AUTOSAR XML (schema 00050)
package /ComponentTypes
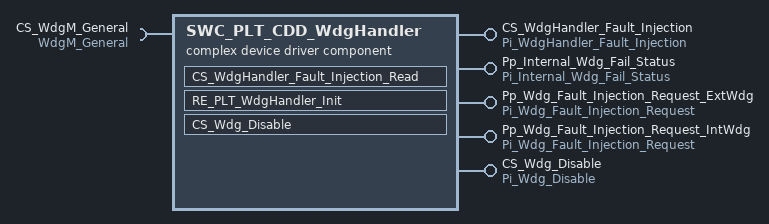
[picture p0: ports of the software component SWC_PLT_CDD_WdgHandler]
  complex device driver sw component type SWC_PLT_CDD_WdgHandler
    5 x provide port:
      CS_WdgHandler_Fault_Injection: server-com-spec{operation=Read, queue-length=1}, provided-interface=Pi_WdgHandler_Fault_Injection
      Pp_Internal_Wdg_Fail_Status: nonqueued-sender-com-spec{data-element=Internal_Wdg_Fail_Status, init-value=0}, provided-interface=Pi_Internal_Wdg_Fail_Status
      Pp_Wdg_Fault_Injection_Request_ExtWdg: nonqueued-sender-com-spec=De_Wdg_Fault_Injection_Request, provided-interface=Pi_Wdg_Fault_Injection_Request
      Pp_Wdg_Fault_Injection_Request_IntWdg: nonqueued-sender-com-spec{data-element=De_Wdg_Fault_Injection_Request, init-value=0}, provided-interface=Pi_Wdg_Fault_Injection_Request
      CS_Wdg_Disable: server-com-spec{operation=Read, queue-length=1}, provided-interface=Pi_Wdg_Disable
    require port CS_WdgM_General: required-interface=WdgM_General
      required-com-specs:
        DeactivateSupervisionEntity
        ActivateSupervisionEntity
        GetFirstExpiredSEID
        SetMode
        PerformReset
        GetLocalStatus
        GetGlobalStatus
        GetMode
    behavior SWC_PLT_CDD_WdgHandler_InternalBehavior: handle-termination-and-restart=NO-SUPPORT
      operation invoked event OIT_CS_WdgHandler_Fault_Injection_Read_CS_WdgHandler_Fault_Injection_Read: start-on-event=CS_WdgHandler_Fault_Injection_Read, operation=CS_WdgHandler_Fault_Injection.Read
      init event SWC_PLT_CDD_WdgHandler_InitEvent: start-on-event=RE_PLT_WdgHandler_Init
      operation invoked event OIT_CS_Wdg_Disable_Read_CS_Wdg_Disable_Read: start-on-event=CS_Wdg_Disable, operation=CS_Wdg_Disable.Read
      runnable CS_WdgHandler_Fault_Injection_Read
      runnable RE_PLT_WdgHandler_Init
        data-send-points:
          access SEND_Pp_Internal_Wdg_Fail_Status_Internal_Wdg_Fail_Status: accessed-variable=Pp_Internal_Wdg_Fail_Status.Internal_Wdg_Fail_Status
          access SEND_Pp_Wdg_Fault_Injection_Request_ExtWdg_De_Wdg_Fault_Injection_Request: accessed-variable=Pp_Wdg_Fault_Injection_Request_ExtWdg.De_Wdg_Fault_Injection_Request
          access SEND_Pp_Wdg_Fault_Injection_Request_IntWdg_De_Wdg_Fault_Injection_Request: accessed-variable=Pp_Wdg_Fault_Injection_Request_IntWdg.De_Wdg_Fault_Injection_Request
      runnable CS_Wdg_Disable: can-be-invoked-concurrently=true
        sync call SC_CS_WdgM_General_SetMode: operation=CS_WdgM_General.SetMode
  swc implementation SWC_PLT_CDD_WdgHandler_Implementation: behavior=SWC_PLT_CDD_WdgHandler_InternalBehavior
    code-descriptors:
      code Default: artifact-descriptors=autosar-engineering-object=category=SWSRC
